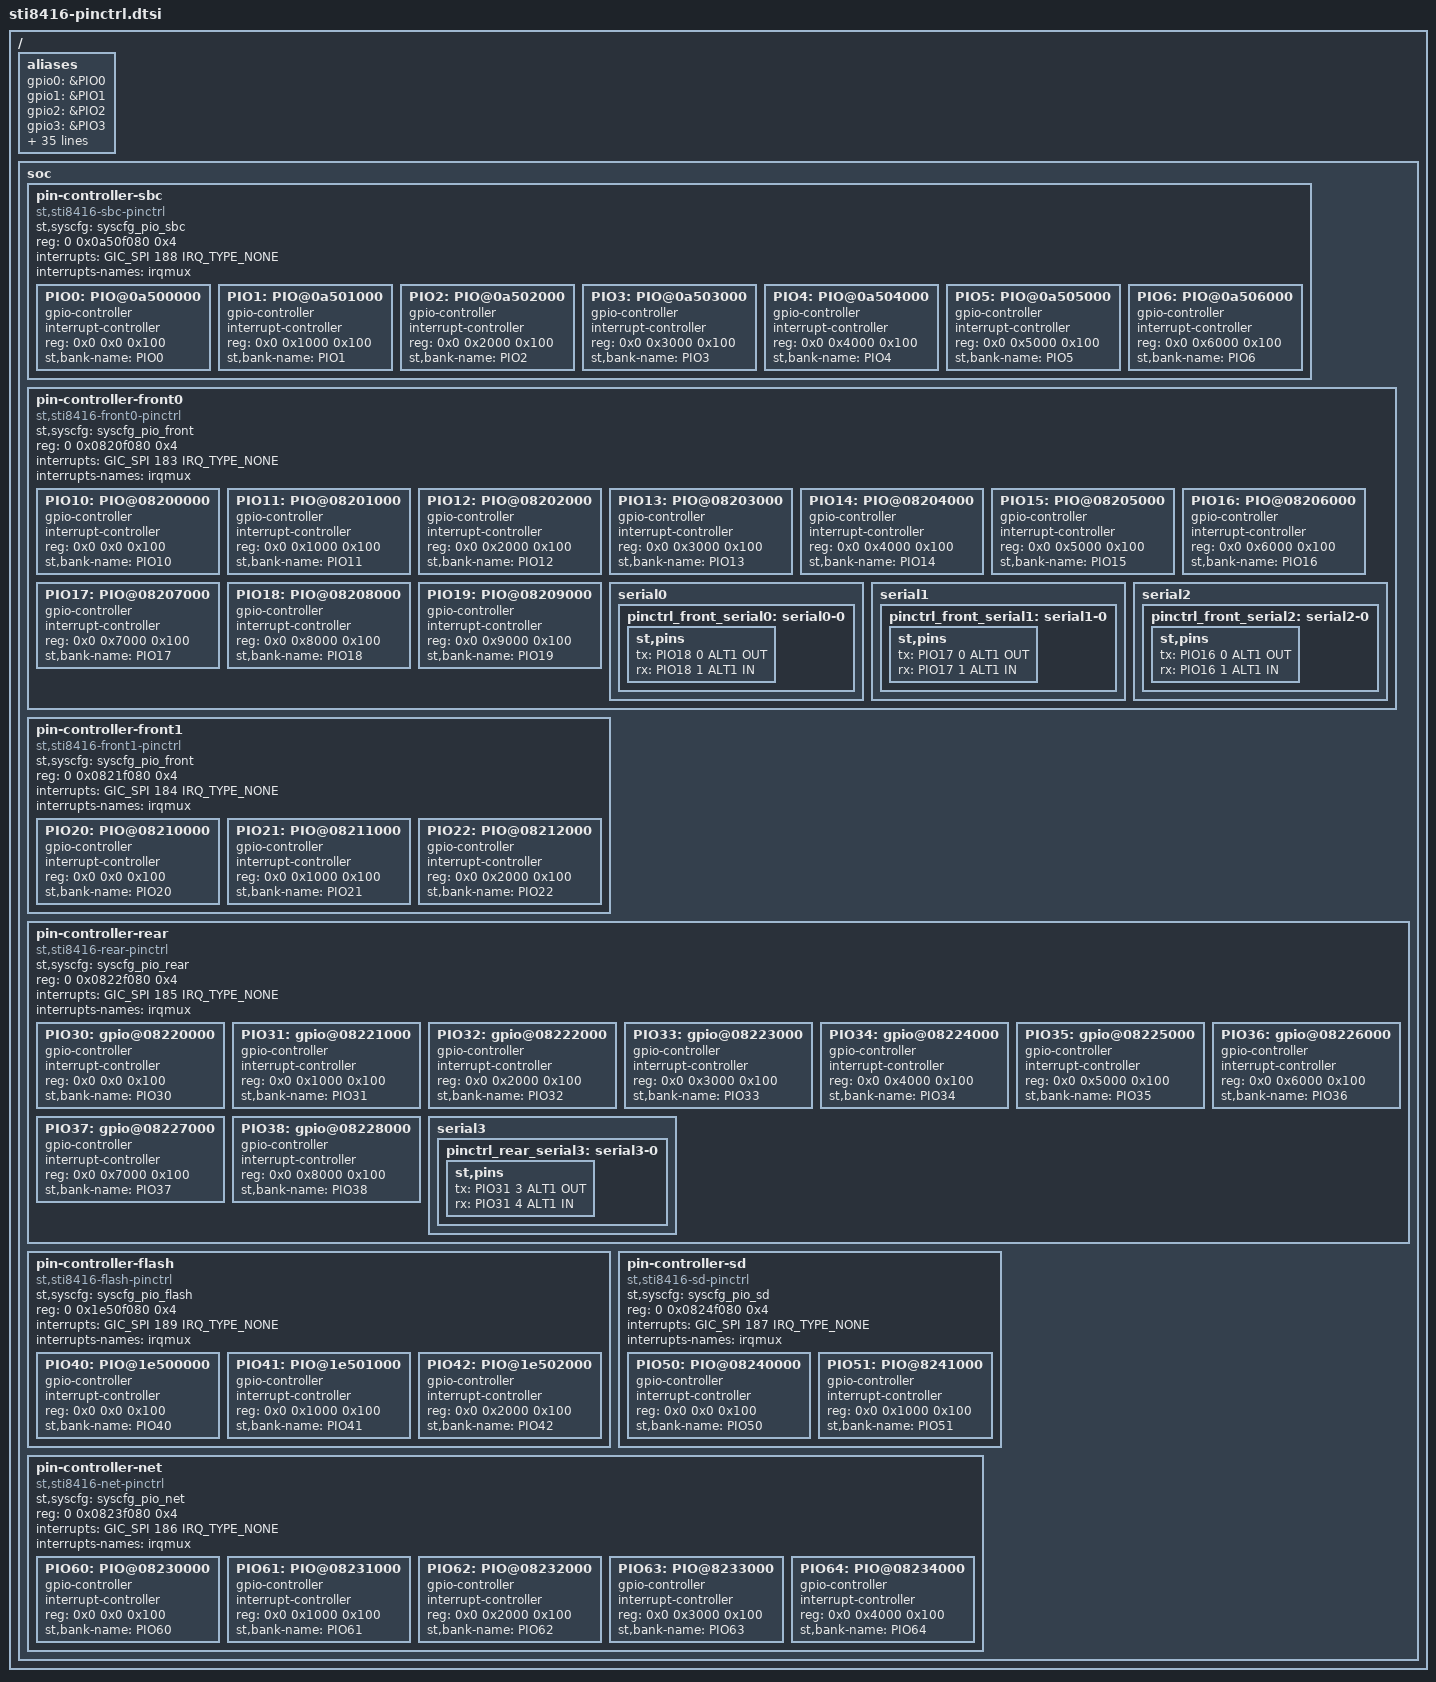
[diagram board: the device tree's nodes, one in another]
/*
 * Copyright (C) 2014 STMicroelectronics Limited.
 * Author: Nunzio Raciti <nunzio.raciti@st.com>
 * Author: Madianga M'boumba Cedric <cedric.madianga@st.com>
 *
 * This program is free software; you can redistribute it and/or modify
 * it under the terms of the GNU General Public License version 2 as
 * publishhed by the Free Software Foundation.
 */

#include <dt-bindings/pinctrl/st-pincfg.h>
#include <dt-bindings/interrupt-controller/arm-gic.h>

/ {
	aliases {
		/* PIO for FC1 VSAFE - 0-6_ PIO_SBC */
		gpio0 = &PIO0;
		gpio1 = &PIO1;
		gpio2 = &PIO2;
		gpio3 = &PIO3;
		gpio4 = &PIO4;
		gpio5 = &PIO5;
		gpio6 = &PIO6;
		/* PIO for FC0 BACKBONE - 10-22: PIO_FRONT */
		gpio7 = &PIO10;
		gpio8 = &PIO11;
		gpio9 = &PIO12;
		gpio10 = &PIO13;
		gpio11 = &PIO14;
		gpio12 = &PIO15;
		gpio13 = &PIO16;
		gpio14 = &PIO17;
		gpio15 = &PIO18;
		gpio16 = &PIO19;
		gpio17 = &PIO20;
		gpio18 = &PIO21;
		gpio19 = &PIO22;
		/* 30-38: PIO_REAR */
		gpio20 = &PIO30;
		gpio21 = &PIO31;
		gpio22 = &PIO32;
		gpio23 = &PIO33;
		gpio24 = &PIO34;
		gpio25 = &PIO35;
		gpio26 = &PIO36;
		gpio27 = &PIO37;
		gpio28 = &PIO38;
		/* PIO for FC11 BOOT - 40-42: PIO_FLASH */
		gpio29 = &PIO40;
		gpio30 = &PIO41;
		gpio31 = &PIO42;
		/* 50-51: PIO_SD */
		gpio32 = &PIO50;
		gpio33 = &PIO51;
		/* 60-64: PIO_NET */
		gpio34 = &PIO60;
		gpio35 = &PIO61;
		gpio36 = &PIO62;
		gpio37 = &PIO63;
		gpio38 = &PIO64;
	};

	soc {
		/* FC1 VSAFE */
		pin-controller-sbc {
			/* PIO SBC */
			#address-cells = <2>;
			#size-cells = <1>;
			compatible = "st,sti8416-sbc-pinctrl";
			st,syscfg = <&syscfg_pio_sbc>;
			reg = <0 0x0a50f080 0x4>;
			reg-names = "irqmux";
			interrupts = <GIC_SPI 188 IRQ_TYPE_NONE>;
			interrupts-names = "irqmux";
			ranges = <0 0 0x0 0x0a500000 0x7000>;

			/* SBC PIOs */
			PIO0: PIO@0a500000 {
				gpio-controller;
				#gpio-cells = <2>;
				interrupt-controller;
				#interrupt-cells = <2>;
				reg = <0x0 0x0 0x100>;
				st,bank-name = "PIO0";
			};

			PIO1: PIO@0a501000 {
				gpio-controller;
				#gpio-cells = <2>;
				interrupt-controller;
				#interrupt-cells = <2>;
				reg = <0x0 0x1000 0x100>;
				st,bank-name = "PIO1";
			};

			PIO2: PIO@0a502000 {
				gpio-controller;
				#gpio-cells = <2>;
				interrupt-controller;
				#interrupt-cells = <2>;
				reg = <0x0 0x2000 0x100>;
				st,bank-name = "PIO2";
			};

			PIO3: PIO@0a503000 {
				gpio-controller;
				#gpio-cells = <2>;
				interrupt-controller;
				#interrupt-cells = <2>;
				reg = <0x0 0x3000 0x100>;
				st,bank-name = "PIO3";
			};

			PIO4: PIO@0a504000 {
				gpio-controller;
				#gpio-cells = <2>;
				interrupt-controller;
				#interrupt-cells = <2>;
				reg = <0x0 0x4000 0x100>;
				st,bank-name = "PIO4";
			};

			PIO5: PIO@0a505000 {
				gpio-controller;
				#gpio-cells = <2>;
				interrupt-controller;
				#interrupt-cells = <2>;
				reg = <0x0 0x5000 0x100>;
				st,bank-name = "PIO5";
			};

			PIO6: PIO@0a506000 {
				gpio-controller;
				#gpio-cells = <2>;
				interrupt-controller;
				#interrupt-cells = <2>;
				reg = <0x0 0x6000 0x100>;
				st,bank-name = "PIO6";
			};
		};

		/* FC0 BACKBONE */
		pin-controller-front0 {
			#address-cells = <2>;
			#size-cells = <1>;
			compatible = "st,sti8416-front0-pinctrl";
			st,syscfg = <&syscfg_pio_front>;
			reg = <0 0x0820f080 0x4>;
			reg-names = "irqmux";
			interrupts = <GIC_SPI 183 IRQ_TYPE_NONE>;
			interrupts-names = "irqmux";
			ranges = <0 0 0x0 0x08200000 0x10000>;

			PIO10: PIO@08200000 {
				gpio-controller;
				#gpio-cells = <2>;
				interrupt-controller;
				#interrupt-cells = <2>;
				reg = <0x0 0x0 0x100>;
				st,bank-name = "PIO10";
			};

			PIO11: PIO@08201000 {
				gpio-controller;
				#gpio-cells = <2>;
				interrupt-controller;
				#interrupt-cells = <2>;
				reg = <0x0 0x1000 0x100>;
				st,bank-name = "PIO11";
			};

			PIO12: PIO@08202000 {
				gpio-controller;
				#gpio-cells = <2>;
				interrupt-controller;
				#interrupt-cells = <2>;
				reg = <0x0 0x2000 0x100>;
				st,bank-name = "PIO12";
			};

			PIO13: PIO@08203000 {
				gpio-controller;
				#gpio-cells = <2>;
				interrupt-controller;
				#interrupt-cells = <2>;
				reg = <0x0 0x3000 0x100>;
				st,bank-name = "PIO13";
			};

			PIO14: PIO@08204000 {
				gpio-controller;
				#gpio-cells = <2>;
				interrupt-controller;
				#interrupt-cells = <2>;
				reg = <0x0 0x4000 0x100>;
				st,bank-name = "PIO14";
			};

			PIO15: PIO@08205000 {
				gpio-controller;
				#gpio-cells = <2>;
				interrupt-controller;
				#interrupt-cells = <2>;
				reg = <0x0 0x5000 0x100>;
				st,bank-name = "PIO15";
			};

			PIO16: PIO@08206000 {
				gpio-controller;
				#gpio-cells = <2>;
				interrupt-controller;
				#interrupt-cells = <2>;
				reg = <0x0 0x6000 0x100>;
				st,bank-name = "PIO16";
			};

			PIO17: PIO@08207000 {
				gpio-controller;
				#gpio-cells = <2>;
				interrupt-controller;
				#interrupt-cells = <2>;
				reg = <0x0 0x7000 0x100>;
				st,bank-name = "PIO17";
			};

			PIO18: PIO@08208000 {
				gpio-controller;
				#gpio-cells = <2>;
				interrupt-controller;
				#interrupt-cells = <2>;
				reg = <0x0 0x8000 0x100>;
				st,bank-name = "PIO18";
			};

			PIO19: PIO@08209000 {
				gpio-controller;
				#gpio-cells = <2>;
				interrupt-controller;
				#interrupt-cells = <2>;
				reg = <0x0 0x9000 0x100>;
				st,bank-name = "PIO19";
			};

			/* Comms */
			serial0 {
				pinctrl_front_serial0: serial0-0 {
					st,pins {
						tx = <&PIO18 0 ALT1 OUT>;
						rx = <&PIO18 1 ALT1 IN>;
					};
				};
			};

			serial1 {
				pinctrl_front_serial1: serial1-0 {
					st,pins {
						tx = <&PIO17 0 ALT1 OUT>;
						rx = <&PIO17 1 ALT1 IN>;
					};
				};
			};

			serial2 {
				pinctrl_front_serial2: serial2-0 {
					st,pins {
						tx = <&PIO16 0 ALT1 OUT>;
						rx = <&PIO16 1 ALT1 IN>;
					};
				};
			};
		};

		pin-controller-front1 {
			#address-cells = <2>;
			#size-cells = <1>;
			compatible = "st,sti8416-front1-pinctrl";
			st,syscfg = <&syscfg_pio_front>;
			reg = <0 0x0821f080 0x4>;
			reg-names = "irqmux";
			interrupts = <GIC_SPI 184 IRQ_TYPE_NONE>;
			interrupts-names = "irqmux";
			ranges = <0 0 0x0 0x08210000 0x3000>;

			PIO20: PIO@08210000 {
				gpio-controller;
				#gpio-cells = <2>;
				interrupt-controller;
				#interrupt-cells = <2>;
				reg = <0x0 0x0 0x100>;
				st,bank-name = "PIO20";
			};

			PIO21: PIO@08211000 {
				gpio-controller;
				#gpio-cells = <2>;
				interrupt-controller;
				#interrupt-cells = <2>;
				reg = <0x0 0x1000 0x100>;
				st,bank-name = "PIO21";
			};

			PIO22: PIO@08212000 {
				gpio-controller;
				#gpio-cells = <2>;
				interrupt-controller;
				#interrupt-cells = <2>;
				reg = <0x0 0x2000 0x100>;
				st,bank-name = "PIO22";
			};
		};

		pin-controller-rear {
			#address-cells = <2>;
			#size-cells = <1>;
			compatible = "st,sti8416-rear-pinctrl";
			st,syscfg = <&syscfg_pio_rear>;
			reg = <0 0x0822f080 0x4>;
			reg-names = "irqmux";
			interrupts = <GIC_SPI 185 IRQ_TYPE_NONE>;
			interrupts-names = "irqmux";
			ranges = <0 0 0x0 0x08220000 0x9000>;

			PIO30: gpio@08220000 {
				gpio-controller;
				#gpio-cells = <2>;
				interrupt-controller;
				#interrupt-cells = <2>;
				reg = <0x0 0x0 0x100>;
				st,bank-name = "PIO30";
			};

			PIO31: gpio@08221000 {
				gpio-controller;
				#gpio-cells = <2>;
				interrupt-controller;
				#interrupt-cells = <2>;
				reg = <0x0 0x1000 0x100>;
				st,bank-name = "PIO31";
			};

			PIO32: gpio@08222000 {
				gpio-controller;
				#gpio-cells = <2>;
				interrupt-controller;
				#interrupt-cells = <2>;
				reg = <0x0 0x2000 0x100>;
				st,bank-name = "PIO32";
			};

			PIO33: gpio@08223000 {
				gpio-controller;
				#gpio-cells = <2>;
				interrupt-controller;
				#interrupt-cells = <2>;
				reg = <0x0 0x3000 0x100>;
				st,bank-name = "PIO33";
			};

			PIO34: gpio@08224000 {
				gpio-controller;
				#gpio-cells = <2>;
				interrupt-controller;
				#interrupt-cells = <2>;
				reg = <0x0 0x4000 0x100>;
				st,bank-name = "PIO34";
			};

			PIO35: gpio@08225000 {
				gpio-controller;
				#gpio-cells = <2>;
				interrupt-controller;
				#interrupt-cells = <2>;
				reg = <0x0 0x5000 0x100>;
				st,bank-name = "PIO35";
			};

			PIO36: gpio@08226000 {
				gpio-controller;
				#gpio-cells = <2>;
				interrupt-controller;
				#interrupt-cells = <2>;
				reg = <0x0 0x6000 0x100>;
				st,bank-name = "PIO36";
			};

			PIO37: gpio@08227000 {
				gpio-controller;
				#gpio-cells = <2>;
				interrupt-controller;
				#interrupt-cells = <2>;
				reg = <0x0 0x7000 0x100>;
				st,bank-name = "PIO37";
			};

			PIO38: gpio@08228000 {
				gpio-controller;
				#gpio-cells = <2>;
				interrupt-controller;
				#interrupt-cells = <2>;
				reg = <0x0 0x8000 0x100>;
				st,bank-name = "PIO38";
			};

			serial3 {
				pinctrl_rear_serial3: serial3-0 {
					st,pins {
						tx = <&PIO31 3 ALT1 OUT>;
						rx = <&PIO31 4 ALT1 IN>;
					};
				};
			};
		};

		pin-controller-flash {
			#address-cells = <2>;
			#size-cells = <1>;
			compatible = "st,sti8416-flash-pinctrl";
			st,syscfg = <&syscfg_pio_flash>;
			reg = <0 0x1e50f080 0x4>;
			reg-names = "irqmux";
			interrupts = <GIC_SPI 189 IRQ_TYPE_NONE>;
			interrupts-names = "irqmux";
			ranges = <0 0 0x0 0x1e500000 0x3000>;

			PIO40: PIO@1e500000 {
				gpio-controller;
				#gpio-cells = <2>;
				interrupt-controller;
				#interrupt-cells = <2>;
				reg = <0x0 0x0 0x100>;
				st,bank-name = "PIO40";
			};

			PIO41: PIO@1e501000 {
				gpio-controller;
				#gpio-cells = <2>;
				interrupt-controller;
				#interrupt-cells = <2>;
				reg = <0x0 0x1000 0x100>;
				st,bank-name = "PIO41";
			};

			PIO42: PIO@1e502000 {
				gpio-controller;
				#gpio-cells = <2>;
				interrupt-controller;
				#interrupt-cells = <2>;
				reg = <0x0 0x2000 0x100>;
				st,bank-name = "PIO42";
			};
		};

		pin-controller-sd {
			#address-cells = <2>;
			#size-cells = <1>;
			compatible = "st,sti8416-sd-pinctrl";
			st,syscfg = <&syscfg_pio_sd>;
			reg = <0 0x0824f080 0x4>;
			reg-names = "irqmux";
			interrupts = <GIC_SPI 187 IRQ_TYPE_NONE>;
			interrupts-names = "irqmux";
			ranges = <0 0 0x0 0x08240000 0x2000>;

			PIO50: PIO@08240000 {
				gpio-controller;
				#gpio-cells = <2>;
				interrupt-controller;
				#interrupt-cells = <2>;
				reg = <0x0 0x0 0x100>;
				st,bank-name = "PIO50";
			};

			PIO51: PIO@8241000 {
				gpio-controller;
				#gpio-cells = <2>;
				interrupt-controller;
				#interrupt-cells = <2>;
				reg = <0x0 0x1000 0x100>;
				st,bank-name = "PIO51";
			};
		};

		pin-controller-net {
			#address-cells = <2>;
			#size-cells = <1>;
			compatible = "st,sti8416-net-pinctrl";
			st,syscfg = <&syscfg_pio_net>;
			reg = <0 0x0823f080 0x4>;
			reg-names = "irqmux";
			interrupts = <GIC_SPI 186 IRQ_TYPE_NONE>;
			interrupts-names = "irqmux";
			ranges = <0 0 0x0 0x08230000 0x5000>;

			PIO60: PIO@08230000 {
				gpio-controller;
				#gpio-cells = <2>;
				interrupt-controller;
				#interrupt-cells = <2>;
				reg = <0x0 0x0 0x100>;
				st,bank-name = "PIO60";
			};

			PIO61: PIO@08231000 {
				gpio-controller;
				#gpio-cells = <2>;
				interrupt-controller;
				#interrupt-cells = <2>;
				reg = <0x0 0x1000 0x100>;
				st,bank-name = "PIO61";
			};

			PIO62: PIO@08232000 {
				gpio-controller;
				#gpio-cells = <2>;
				interrupt-controller;
				#interrupt-cells = <2>;
				reg = <0x0 0x2000 0x100>;
				st,bank-name = "PIO62";
			};

			PIO63: PIO@8233000 {
				gpio-controller;
				#gpio-cells = <2>;
				interrupt-controller;
				#interrupt-cells = <2>;
				reg = <0x0 0x3000 0x100>;
				st,bank-name = "PIO63";
			};

			PIO64: PIO@08234000 {
				gpio-controller;
				#gpio-cells = <2>;
				interrupt-controller;
				#interrupt-cells = <2>;
				reg = <0x0 0x4000 0x100>;
				st,bank-name = "PIO64";
			};
		};
	};
};
